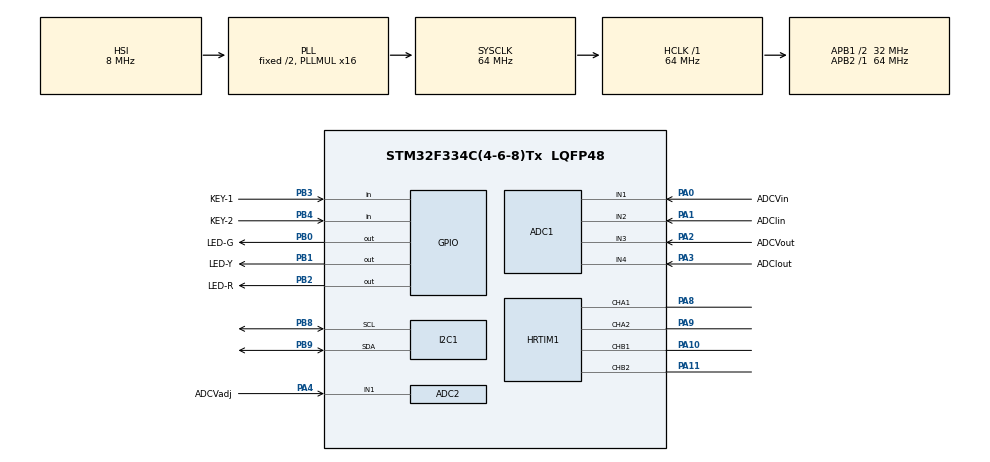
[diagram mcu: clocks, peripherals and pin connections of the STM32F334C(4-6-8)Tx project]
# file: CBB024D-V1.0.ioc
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ADC1.Channel-5\#ChannelRegularConversion=ADC_CHANNEL_1
ADC1.Channel-6\#ChannelRegularConversion=ADC_CHANNEL_2
ADC1.Channel-7\#ChannelRegularConversion=ADC_CHANNEL_3
ADC1.Channel-8\#ChannelRegularConversion=ADC_CHANNEL_4
ADC1.ClockPrescaler=ADC_CLOCK_SYNC_PCLK_DIV4
ADC1.DMAContinuousRequests=ENABLE
ADC1.EOCSelection=ADC_EOC_SEQ_CONV
ADC1.EnableInjectedConversion=DISABLE
ADC1.EnableRegularConversion=ENABLE
ADC1.ExternalTrigConv=ADC_EXTERNALTRIGCONVHRTIM_TRG1
ADC1.NbrOfConversion=4
ADC1.NbrOfConversionFlag=1
ADC1.Offset-5\#ChannelRegularConversion=0
ADC1.Offset-6\#ChannelRegularConversion=0
ADC1.Offset-7\#ChannelRegularConversion=0
ADC1.Offset-8\#ChannelRegularConversion=0
ADC1.OffsetNumber-5\#ChannelRegularConversion=ADC_OFFSET_NONE
ADC1.OffsetNumber-6\#ChannelRegularConversion=ADC_OFFSET_NONE
ADC1.OffsetNumber-7\#ChannelRegularConversion=ADC_OFFSET_NONE
ADC1.OffsetNumber-8\#ChannelRegularConversion=ADC_OFFSET_NONE
ADC1.Rank-5\#ChannelRegularConversion=1
ADC1.Rank-6\#ChannelRegularConversion=2
ADC1.Rank-7\#ChannelRegularConversion=3
ADC1.Rank-8\#ChannelRegularConversion=4
ADC1.SamplingTime-5\#ChannelRegularConversion=ADC_SAMPLETIME_4CYCLES_5
ADC1.SamplingTime-6\#ChannelRegularConversion=ADC_SAMPLETIME_4CYCLES_5
ADC1.SamplingTime-7\#ChannelRegularConversion=ADC_SAMPLETIME_4CYCLES_5
ADC1.SamplingTime-8\#ChannelRegularConversion=ADC_SAMPLETIME_4CYCLES_5
ADC1.SequencerNbRanks=1
ADC1.master=1
ADC2.Channel-0\#ChannelRegularConversion=ADC_CHANNEL_1
ADC2.ClockPrescaler=ADC_CLOCK_SYNC_PCLK_DIV4
ADC2.ContinuousConvMode=ENABLE
ADC2.EnableInjectedConversion=DISABLE
ADC2.NbrOfConversionFlag=1
ADC2.Offset-0\#ChannelRegularConversion=0
ADC2.OffsetNumber-0\#ChannelRegularConversion=ADC_OFFSET_NONE
ADC2.Rank-0\#ChannelRegularConversion=1
ADC2.SamplingTime-0\#ChannelRegularConversion=ADC_SAMPLETIME_7CYCLES_5
ADC2.SamplingTimeOPAMP-0\#ChannelRegularConversion=ADC_SAMPLETIME_61CYCLES_5
Dma.ADC1.0.Direction=DMA_PERIPH_TO_MEMORY
Dma.ADC1.0.Instance=DMA1_Channel1
Dma.ADC1.0.MemDataAlignment=DMA_MDATAALIGN_HALFWORD
Dma.ADC1.0.MemInc=DMA_MINC_ENABLE
Dma.ADC1.0.Mode=DMA_CIRCULAR
Dma.ADC1.0.PeriphDataAlignment=DMA_PDATAALIGN_HALFWORD
Dma.ADC1.0.PeriphInc=DMA_PINC_DISABLE
Dma.ADC1.0.Priority=DMA_PRIORITY_HIGH
Dma.Request0=ADC1
HRTIM1.ADCTrigger1_Source1=HRTIM_ADCTRIGGEREVENT13_TIMERA_CMP3
HRTIM1.ADCTrigger_Id1=HRTIM_ADCTRIGGER_1
HRTIM1.CompareUnit1-Output_TA1TA2=HRTIM_COMPAREUNIT_1
HRTIM1.CompareUnit1-Output_TB1TB2=HRTIM_COMPAREUNIT_1
HRTIM1.CompareUnit3-Output_TA1TA2=HRTIM_COMPAREUNIT_3
HRTIM1.CompareValue1-Output_TA1TA2=5000
HRTIM1.CompareValue1-Output_TB1TB2=9000
HRTIM1.CompareValue3-Output_TA1TA2=2500
HRTIM1.Configuration_TA=Waveform
HRTIM1.DeadTimeInsertion-Output_TA1TA2=HRTIM_TIMDEADTIMEINSERTION_ENABLED
HRTIM1.DeadTimeInsertion-Output_TB1TB2=HRTIM_TIMDEADTIMEINSERTION_ENABLED
HRTIM1.FallingLock-Output_TA1TA2=HRTIM_TIMDEADTIME_FALLINGLOCK_READONLY
HRTIM1.FallingLock-Output_TB1TB2=HRTIM_TIMDEADTIME_FALLINGLOCK_READONLY
HRTIM1.FallingSignLock-Output_TA1TA2=HRTIM_TIMDEADTIME_FALLINGSIGNLOCK_READONLY
HRTIM1.FallingSignLock-Output_TB1TB2=HRTIM_TIMDEADTIME_FALLINGSIGNLOCK_READONLY
HRTIM1.FallingValue-Output_TA1TA2=180
HRTIM1.FallingValue-Output_TB1TB2=180
HRTIM1.FaultLock-Output_TA1TA2=HRTIM_TIMFAULTLOCK_READONLY
HRTIM1.FaultLock-Output_TB1TB2=HRTIM_TIMFAULTLOCK_READONLY
HRTIM1.InterruptRequests1-Output_TA1TA2=HRTIM_TIM_IT_REP
HRTIM1.NumberADCTriggerSource1=1
HRTIM1.NumberInterruptRequests-Output_TA1TA2=1
HRTIM1.NumberResetSource1-Output_TA1TA2=1
HRTIM1.NumberResetSource1-Output_TB1TB2=1
HRTIM1.NumberSetSource1-Output_TA1TA2=1
HRTIM1.NumberSetSource1-Output_TB1TB2=1
HRTIM1.NumberUpdateTrigger-Output_TA1TA2=0
HRTIM1.ORingUpdateSource_ADCTrigger1=HRTIM_ADCTRIGGERUPDATE_TIMER_B
HRTIM1.Periode_TA=10240
HRTIM1.Periode_TB=10240
HRTIM1.PreloadEnable-Output_TA1TA2=HRTIM_PRELOAD_ENABLED
HRTIM1.PreloadEnable-Output_TB1TB2=HRTIM_PRELOAD_ENABLED
HRTIM1.PrescalerRatio_TA=HRTIM_PRESCALERRATIO_MUL16
HRTIM1.PrescalerRatio_TB=HRTIM_PRESCALERRATIO_MUL16
HRTIM1.RepetitionCounter-Output_TA1TA2=0
HRTIM1.RepetitionUpdate-Output_TA1TA2=HRTIM_UPDATEONREPETITION_ENABLED
HRTIM1.RepetitionUpdate-Output_TB1TB2=HRTIM_UPDATEONREPETITION_ENABLED
HRTIM1.ResetOutput1_Source1-Output_TA1TA2=HRTIM_OUTPUTRESET_TIMCMP1
HRTIM1.ResetOutput1_Source1-Output_TB1TB2=HRTIM_OUTPUTRESET_TIMCMP1
HRTIM1.RisingLock-Output_TA1TA2=HRTIM_TIMDEADTIME_RISINGLOCK_READONLY
HRTIM1.RisingLock-Output_TB1TB2=HRTIM_TIMDEADTIME_RISINGLOCK_READONLY
HRTIM1.RisingSignLock-Output_TA1TA2=HRTIM_TIMDEADTIME_RISINGSIGNLOCK_READONLY
HRTIM1.RisingSignLock-Output_TB1TB2=HRTIM_TIMDEADTIME_RISINGSIGNLOCK_READONLY
HRTIM1.RisingValue-Output_TA1TA2=180
HRTIM1.RisingValue-Output_TB1TB2=180
HRTIM1.SetOutput1_Source1-Output_TA1TA2=HRTIM_OUTPUTSET_TIMPER
HRTIM1.SetOutput1_Source1-Output_TB1TB2=HRTIM_OUTPUTSET_TIMPER
Mcu.Family=STM32F3
Mcu.Name=STM32F334C(4-6-8)Tx
Mcu.Package=LQFP48
NVIC.HRTIM1_TIMA_IRQn=true\:1\:0\:true\:false\:true\:true\:true
NVIC.PriorityGroup=NVIC_PRIORITYGROUP_4
NVIC.TIM3_IRQn=true\:2\:0\:true\:false\:true\:true\:true
PA0.GPIO_Label=ADCVin
PA0.Mode=IN1-Single-Ended
PA0.Signal=ADC1_IN1
PA1.GPIO_Label=ADCIin
PA1.Mode=IN2-Single-Ended
PA1.Signal=ADC1_IN2
PA10.Mode=Output_TB1TB2
PA10.Signal=HRTIM1_CHB1
PA11.Mode=Output_TB1TB2
PA11.Signal=HRTIM1_CHB2
PA13.Mode=Serial_Wire
PA13.Signal=SYS_JTMS-SWDIO
PA14.Mode=Serial_Wire
PA14.Signal=SYS_JTCK-SWCLK
PA2.GPIO_Label=ADCVout
PA2.Mode=IN3-Single-Ended
PA2.Signal=ADC1_IN3
PA3.GPIO_Label=ADCIout
PA3.Mode=IN4-Single-Ended
PA3.Signal=ADC1_IN4
PA4.GPIO_Label=ADCVadj
PA4.Mode=IN1-Single-Ended
PA4.Signal=ADC2_IN1
PA8.GPIO_PuPd=GPIO_PULLUP
PA8.Mode=Output_TA1TA2
PA8.Signal=HRTIM1_CHA1
PA9.GPIO_PuPd=GPIO_PULLUP
PA9.Mode=Output_TA1TA2
PA9.Signal=HRTIM1_CHA2
PB0.GPIO_Label=LED-G
PB0.GPIO_PuPd=GPIO_PULLUP
PB0.GPIO_Speed=GPIO_SPEED_FREQ_HIGH
PB0.Signal=GPIO_Output
PB1.GPIO_Label=LED-Y
PB1.GPIO_PuPd=GPIO_PULLUP
PB1.GPIO_Speed=GPIO_SPEED_FREQ_HIGH
PB1.Signal=GPIO_Output
PB2.GPIO_Label=LED-R
PB2.GPIO_PuPd=GPIO_PULLUP
PB2.GPIO_Speed=GPIO_SPEED_FREQ_HIGH
PB2.Signal=GPIO_Output
PB3.GPIO_Label=KEY-1
PB3.GPIO_PuPd=GPIO_PULLUP
PB3.Signal=GPIO_Input
PB4.GPIO_Label=KEY-2
PB4.GPIO_PuPd=GPIO_PULLUP
PB4.Signal=GPIO_Input
PB8.Mode=I2C
PB8.Signal=I2C1_SCL
PB9.Mode=I2C
PB9.Signal=I2C1_SDA
ProjectManager.HeapSize=0x200
ProjectManager.StackSize=0x400
ProjectManager.TargetToolchain=MDK-ARM V5.27
RCC.AHBFreq_Value=64000000
RCC.APB1CLKDivider=RCC_HCLK_DIV2
RCC.APB1Freq_Value=32000000
RCC.APB1TimFreq_Value=64000000
RCC.APB2Freq_Value=64000000
RCC.APB2TimFreq_Value=64000000
RCC.CortexFreq_Value=64000000
RCC.HCLKFreq_Value=64000000
RCC.HRTIMSelection=RCC_HRTIM1CLK_PLLCLK
RCC.HSE_VALUE=8000000
RCC.HSI_VALUE=8000000
RCC.LSE_VALUE=32768
RCC.PLLMUL=RCC_PLL_MUL16
RCC.SYSCLKFreq_VALUE=64000000
RCC.SYSCLKSourceVirtual=RCC_SYSCLKSOURCE_PLLCLK
TIM3.Period=10000
TIM3.Prescaler=32
VP_TIM3_VS_ClockSourceINT.Mode=Internal
VP_TIM3_VS_ClockSourceITR.Mode=TriggerSource_ITR0
board=custom

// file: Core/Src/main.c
/* USER CODE BEGIN Header */
/****************************************************************************************
	*
	* @author  文七电源
	* @淘宝店铺链接：https://shop598739109.taobao.com
	* @file           : main.c
  * @brief          : Main program body
  * @version V1.0
  * @date    01-03-2021
  * @LegalDeclaration ：本文档内容难免存在Bug，仅限于交流学习，禁止用于任何的商业用途
	* @Copyright   著作权文七电源所有
  * @attention
  *
  * <h2><center>&copy; Copyright (c) 2021 STMicroelectronics.
  * All rights reserved.</center></h2>
  *
  * This software component is licensed by ST under BSD 3-Clause license,
  * the "License"; You may not use this file except in compliance with the
  * License. You may obtain a copy of the License at:
  *                        opensource.org/licenses/BSD-3-Clause
  *
  ******************************************************************************
  */

/* USER CODE END Header */
#include "main.h"
#include "adc.h"
#include "dma.h"
#include "hrtim.h"
#include "hrtim.h"
#include "i2c.h"
#include "tim.h"
#include "gpio.h"

/* USER CODE BEGIN Includes */
#include "oled.h"
#include "function.h"
/* USER CODE END Includes */

void SystemClock_Config(void);

int main(void)
{

  /* MCU Configuration--------------------------------------------------------*/

  /* Reset of all peripherals, Initializes the Flash interface and the Systick. */
  HAL_Init();

  /* Configure the system clock */
  SystemClock_Config();

  /* Initialize all configured peripherals */
  MX_GPIO_Init();
  MX_DMA_Init();
  MX_HRTIM1_Init();
  MX_ADC1_Init();
  MX_ADC2_Init();
  MX_I2C1_Init();
  MX_TIM3_Init();
  /* USER CODE BEGIN 2 */
	MX_OLED_Init();//OLED显示屏初始化
	HAL_TIM_Base_Start_IT(&htim3);//启动定时器2 200Hz
	HAL_ADC_Start_DMA(&hadc1, (uint32_t*)ADC1_RESULT, 4);//启动ADC1采样 DMA数据传送采样输入输出电压电流
	HAL_ADC_Start(&hadc2);//启动ADC2采样，采样滑动电位器电压
	HAL_HRTIM_WaveformOutputStart(&hhrtim1, HRTIM_OUTPUT_TA1|HRTIM_OUTPUT_TA2); //开启PWM输出和PWM计时器
	HAL_HRTIM_WaveformOutputStart(&hhrtim1, HRTIM_OUTPUT_TB1|HRTIM_OUTPUT_TB2); //开启PWM输出和PWM计时器
	HAL_HRTIM_WaveformCountStart(&hhrtim1, HRTIM_TIMERID_TIMER_A);//开启PWM输出和PWM计时器
	HAL_HRTIM_WaveformCountStart(&hhrtim1, HRTIM_TIMERID_TIMER_B);//开启PWM输出和PWM计时器
	__HAL_HRTIM_TIMER_ENABLE_IT(&hhrtim1,HRTIM_TIMERINDEX_TIMER_A,HRTIM_TIM_IT_REP);
	/*HAL_NVIC_SetPriority(HRTIM1_TIMA_IRQn,1,0); //抢占优先级为3，子优先级为3
  HAL_NVIC_EnableIRQ(HRTIM1_TIMA_IRQn); //使能中断线13
	HAL_NVIC_SetPriority(TIM2_IRQn,2,0); //抢占优先级为3，子优先级为3
  HAL_NVIC_EnableIRQ(TIM2_IRQn); //使能中断线13*/
  /* USER CODE END 2 */

  /* Infinite loop */
  while (1)
  {

    /* USER CODE BEGIN 3 */
		if(OLEDShowCnt>60)//300m刷新一次
		{
			OLEDShowCnt=0;
			OLEDShow();
		}
  }
  /* USER CODE END 3 */
}

void SystemClock_Config(void)
{
  RCC_OscInitTypeDef RCC_OscInitStruct = {0};
  RCC_ClkInitTypeDef RCC_ClkInitStruct = {0};
  RCC_PeriphCLKInitTypeDef PeriphClkInit = {0};

  /** Initializes the RCC Oscillators according to the specified parameters
  * in the RCC_OscInitTypeDef structure.
  */
  RCC_OscInitStruct.OscillatorType = RCC_OSCILLATORTYPE_HSI;
  RCC_OscInitStruct.HSIState = RCC_HSI_ON;
  RCC_OscInitStruct.HSICalibrationValue = RCC_HSICALIBRATION_DEFAULT;
  RCC_OscInitStruct.PLL.PLLState = RCC_PLL_ON;
  RCC_OscInitStruct.PLL.PLLSource = RCC_PLLSOURCE_HSI;
  RCC_OscInitStruct.PLL.PLLMUL = RCC_PLL_MUL16;
  if (HAL_RCC_OscConfig(&RCC_OscInitStruct) != HAL_OK)
  {
    Error_Handler();
  }
  /** Initializes the CPU, AHB and APB buses clocks
  */
  RCC_ClkInitStruct.ClockType = RCC_CLOCKTYPE_HCLK|RCC_CLOCKTYPE_SYSCLK
                              |RCC_CLOCKTYPE_PCLK1|RCC_CLOCKTYPE_PCLK2;
  RCC_ClkInitStruct.SYSCLKSource = RCC_SYSCLKSOURCE_PLLCLK;
  RCC_ClkInitStruct.AHBCLKDivider = RCC_SYSCLK_DIV1;
  RCC_ClkInitStruct.APB1CLKDivider = RCC_HCLK_DIV2;
  RCC_ClkInitStruct.APB2CLKDivider = RCC_HCLK_DIV1;

  if (HAL_RCC_ClockConfig(&RCC_ClkInitStruct, FLASH_LATENCY_2) != HAL_OK)
  {
    Error_Handler();
  }
  PeriphClkInit.PeriphClockSelection = RCC_PERIPHCLK_HRTIM1|RCC_PERIPHCLK_I2C1;
  PeriphClkInit.I2c1ClockSelection = RCC_I2C1CLKSOURCE_HSI;
  PeriphClkInit.Hrtim1ClockSelection = RCC_HRTIM1CLK_PLLCLK;
  if (HAL_RCCEx_PeriphCLKConfig(&PeriphClkInit) != HAL_OK)
  {
    Error_Handler();
  }
}

void Error_Handler(void)
{
  __disable_irq();
  while (1)
  {
  }
}

/************************ (C) COPYRIGHT STMicroelectronics *****END OF FILE****/
